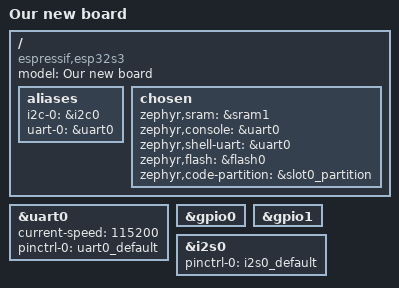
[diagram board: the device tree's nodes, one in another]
/*
 * Copyright (c) 2024-2025 Espressif Systems (Shanghai) Co., Ltd.
 *
 * SPDX-License-Identifier: Apache-2.0
 */
/dts-v1/;

#include <espressif/esp32s3/esp32s3_wroom_n8.dtsi>
#include <espressif/partitions_0x0_amp.dtsi>
#include "esp32s3_devkitc-pinctrl.dtsi"

/ {
	model = "Our new board";
	compatible = "espressif,esp32s3";

	aliases {
		i2c-0 = &i2c0;
		uart-0 = &uart0;

	};

	chosen {
		zephyr,sram = &sram1;
		zephyr,console = &uart0;
		zephyr,shell-uart = &uart0;
		zephyr,flash = &flash0;
		zephyr,code-partition = &slot0_partition;
	};
};


&uart0 {
	status = "okay";
	current-speed = <115200>;
	pinctrl-0 = <&uart0_default>;
	pinctrl-names = "default";
};

&gpio0 {
	status = "okay";
};

&gpio1 {
	status = "okay";
};

&i2s0 {
	pinctrl-0 = <&i2s0_default>;
	pinctrl-names = "default";
};
